AUTOSAR XML (schema 4-2-2)
package /STELLANTIS/EPT/SASWCs
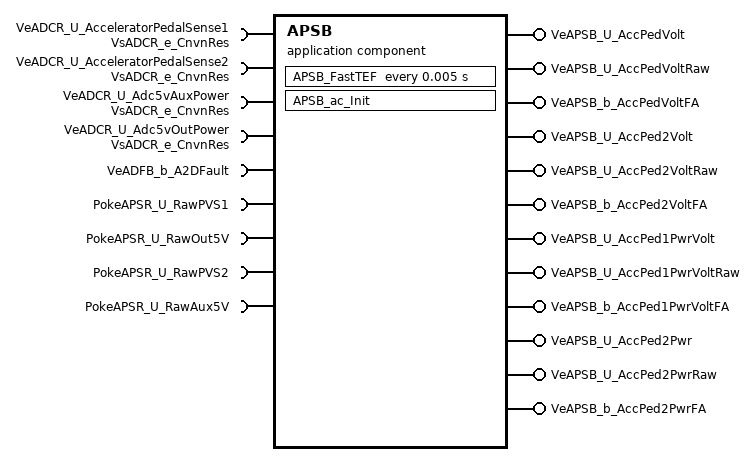
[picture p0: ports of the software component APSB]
  application sw component type APSB
    5 x require port:
      VeADCR_U_AcceleratorPedalSense1: nonqueued-receiver-com-spec{data-element=VsADCR_e_CnvnRes, init-value={short-label=DefaultInitValue_IDTRAdcInpResData, fields=[0, 0]}}, required-interface=VsADCR_e_CnvnRes
      VeADCR_U_AcceleratorPedalSense2: nonqueued-receiver-com-spec{data-element=VsADCR_e_CnvnRes, init-value={short-label=DefaultInitValue_IDTRAdcInpResData, fields=[0, 0]}}, required-interface=VsADCR_e_CnvnRes
      VeADCR_U_Adc5vAuxPower: nonqueued-receiver-com-spec{data-element=VsADCR_e_CnvnRes, init-value={short-label=DefaultInitValue_IDTRAdcInpResData, fields=[0, 0]}}, required-interface=VsADCR_e_CnvnRes
      VeADCR_U_Adc5vOutPower: nonqueued-receiver-com-spec{data-element=VsADCR_e_CnvnRes, init-value={short-label=DefaultInitValue_IDTRAdcInpResData, fields=[0, 0]}}, required-interface=VsADCR_e_CnvnRes
      VeADFB_b_A2DFault: nonqueued-receiver-com-spec{data-element=Value, init-value=0}, required-interface=VeADFB_b_A2DFault
    12 x provide port, all with nonqueued-sender-com-spec{data-element=Value, init-value=0}:
      VeAPSB_U_AccPedVolt: provided-interface=VeAPSB_U_AccPedVolt
      VeAPSB_U_AccPedVoltRaw: provided-interface=VeAPSB_U_AccPedVoltRaw
      VeAPSB_b_AccPedVoltFA: provided-interface=VeAPSB_b_AccPedVoltFA
      VeAPSB_U_AccPed2Volt: provided-interface=VeAPSB_U_AccPed2Volt
      VeAPSB_U_AccPed2VoltRaw: provided-interface=VeAPSB_U_AccPed2VoltRaw
      VeAPSB_b_AccPed2VoltFA: provided-interface=VeAPSB_b_AccPed2VoltFA
      VeAPSB_U_AccPed1PwrVolt: provided-interface=VeAPSB_U_AccPed1PwrVolt
      VeAPSB_U_AccPed1PwrVoltRaw: provided-interface=VeAPSB_U_AccPed1PwrVoltRaw
      VeAPSB_b_AccPed1PwrVoltFA: provided-interface=VeAPSB_b_AccPed1PwrVoltFA
      VeAPSB_U_AccPed2Pwr: provided-interface=VeAPSB_U_AccPed2Pwr
      VeAPSB_U_AccPed2PwrRaw: provided-interface=VeAPSB_U_AccPed2PwrRaw
      VeAPSB_b_AccPed2PwrFA: provided-interface=VeAPSB_b_AccPed2PwrFA
    4 x require port:
      PokeAPSR_U_RawPVS1: client-com-spec=PokeAPSR_U_RawPVS1, required-interface=PokeAPSR_U_RawPVS1
      PokeAPSR_U_RawOut5V: client-com-spec=PokeAPSR_U_RawOut5V, required-interface=PokeAPSR_U_RawOut5V
      PokeAPSR_U_RawPVS2: client-com-spec=PokeAPSR_U_RawPVS2, required-interface=PokeAPSR_U_RawPVS2
      PokeAPSR_U_RawAux5V: client-com-spec=PokeAPSR_U_RawAux5V, required-interface=PokeAPSR_U_RawAux5V
    behavior IB_APSB: data-type-mapping=[msADTtoIDTMapping, ADTtoIDTMapping], handle-termination-and-restart=NO-SUPPORT
      timing event Event_FastTEF: start-on-event=APSB_FastTEF, period=0.005
      init event Event_APSB_ac_Init: start-on-event=APSB_ac_Init
      runnable APSB_ac_Init
        data-send-points:
          8 x access:
            OUT_VeAPSB_U_AccPedVolt_Value: accessed-variable=VeAPSB_U_AccPedVolt.Value
            OUT_VeAPSB_U_AccPedVoltRaw_Value: accessed-variable=VeAPSB_U_AccPedVoltRaw.Value
            OUT_VeAPSB_U_AccPed2Volt_Value: accessed-variable=VeAPSB_U_AccPed2Volt.Value
            OUT_VeAPSB_U_AccPed2VoltRaw_Value: accessed-variable=VeAPSB_U_AccPed2VoltRaw.Value
            OUT_VeAPSB_U_AccPed1PwrVolt_Value: accessed-variable=VeAPSB_U_AccPed1PwrVolt.Value
            OUT_VeAPSB_U_AccPed1PwrVoltRaw_Value: accessed-variable=VeAPSB_U_AccPed1PwrVoltRaw.Value
            OUT_VeAPSB_U_AccPed2Pwr_Value: accessed-variable=VeAPSB_U_AccPed2Pwr.Value
            OUT_VeAPSB_U_AccPed2PwrRaw_Value: accessed-variable=VeAPSB_U_AccPed2PwrRaw.Value
      runnable APSB_FastTEF
        data-receive-point-by-arguments:
          5 x access:
            IN_VeADCR_U_AcceleratorPedalSense1_VsADCR_e_CnvnRes: accessed-variable=VeADCR_U_AcceleratorPedalSense1.VsADCR_e_CnvnRes
            IN_VeADCR_U_AcceleratorPedalSense2_VsADCR_e_CnvnRes: accessed-variable=VeADCR_U_AcceleratorPedalSense2.VsADCR_e_CnvnRes
            IN_VeADCR_U_Adc5vAuxPower_VsADCR_e_CnvnRes: accessed-variable=VeADCR_U_Adc5vAuxPower.VsADCR_e_CnvnRes
            IN_VeADCR_U_Adc5vOutPower_VsADCR_e_CnvnRes: accessed-variable=VeADCR_U_Adc5vOutPower.VsADCR_e_CnvnRes
            IN_VeADFB_b_A2DFault_Value: accessed-variable=VeADFB_b_A2DFault.Value
        data-send-points:
          12 x access:
            OUT_VeAPSB_U_AccPedVoltRaw_Value: accessed-variable=VeAPSB_U_AccPedVoltRaw.Value
            OUT_VeAPSB_U_AccPedVolt_Value: accessed-variable=VeAPSB_U_AccPedVolt.Value
            OUT_VeAPSB_b_AccPedVoltFA_Value: accessed-variable=VeAPSB_b_AccPedVoltFA.Value
            OUT_VeAPSB_U_AccPed2VoltRaw_Value: accessed-variable=VeAPSB_U_AccPed2VoltRaw.Value
            OUT_VeAPSB_U_AccPed2Volt_Value: accessed-variable=VeAPSB_U_AccPed2Volt.Value
            OUT_VeAPSB_b_AccPed2VoltFA_Value: accessed-variable=VeAPSB_b_AccPed2VoltFA.Value
            OUT_VeAPSB_U_AccPed1PwrVoltRaw_Value: accessed-variable=VeAPSB_U_AccPed1PwrVoltRaw.Value
            OUT_VeAPSB_U_AccPed1PwrVolt_Value: accessed-variable=VeAPSB_U_AccPed1PwrVolt.Value
            OUT_VeAPSB_b_AccPed1PwrVoltFA_Value: accessed-variable=VeAPSB_b_AccPed1PwrVoltFA.Value
            OUT_VeAPSB_U_AccPed2PwrRaw_Value: accessed-variable=VeAPSB_U_AccPed2PwrRaw.Value
            OUT_VeAPSB_U_AccPed2Pwr_Value: accessed-variable=VeAPSB_U_AccPed2Pwr.Value
            OUT_VeAPSB_b_AccPed2PwrFA_Value: accessed-variable=VeAPSB_b_AccPed2PwrFA.Value
        4 x sync call, all with timeout=1E-06:
          SC_PokeAPSR_U_RawAux5V_PokeAPSR_U_RawAux5V: operation=PokeAPSR_U_RawAux5V.PokeAPSR_U_RawAux5V
          SC_PokeAPSR_U_RawOut5V_PokeAPSR_U_RawOut5V: operation=PokeAPSR_U_RawOut5V.PokeAPSR_U_RawOut5V
          SC_PokeAPSR_U_RawPVS1_PokeAPSR_U_RawPVS1: operation=PokeAPSR_U_RawPVS1.PokeAPSR_U_RawPVS1
          SC_PokeAPSR_U_RawPVS2_PokeAPSR_U_RawPVS2: operation=PokeAPSR_U_RawPVS2.PokeAPSR_U_RawPVS2
